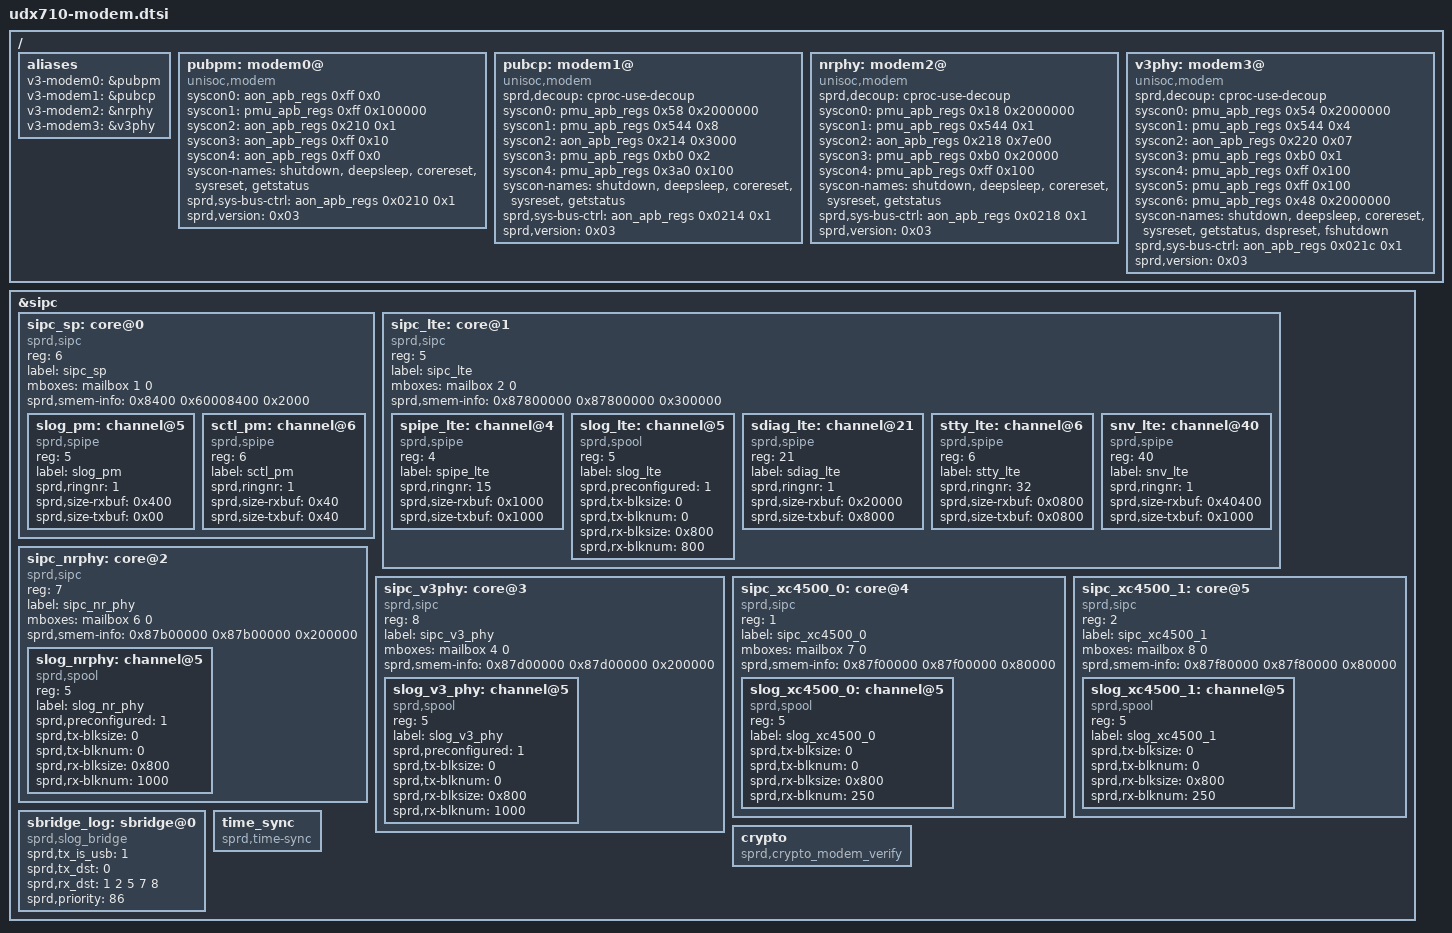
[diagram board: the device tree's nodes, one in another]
// SPDX-License-Identifier: GPL-2.0-only
/*
 * Unisoc UDX710 MODEM board DTSI file
 * This dt is used for modem drivers
 *
 * Copyright (C) 2018, Unisoc (Shanghai) Technologies Co., Ltd
 *
 * This file is licensed under a dual GPLv2 or X11 license.
 */
/ {
	aliases {
		v3-modem0 = &pubpm;
		v3-modem1 = &pubcp;
		v3-modem2 = &nrphy;
		v3-modem3 = &v3phy;
	};

	pubpm: modem0@ {
		compatible = "unisoc,modem";
		syscon0 = <&aon_apb_regs 0xff 0x0>;
		syscon1 = <&pmu_apb_regs 0xff 0x100000>;
		syscon2 = <&aon_apb_regs 0x210 0x1>;
		syscon3 = <&aon_apb_regs 0xff 0x10>;
		syscon4 = <&aon_apb_regs 0xff 0x0>;
		syscon-names = "shutdown", "deepsleep", "corereset",
				       "sysreset", "getstatus";
		sprd,sys-bus-ctrl = <&aon_apb_regs 0x0210 0x1>;
		sprd,version = <0x03>;
	};

	pubcp: modem1@ {
		compatible = "unisoc,modem";
		sprd,decoup = "cproc-use-decoup";
		syscon0 = <&pmu_apb_regs 0x58 0x2000000>;
		syscon1 = <&pmu_apb_regs 0x544 0x8>;
		syscon2 = <&aon_apb_regs 0x214 0x3000>;
		syscon3 = <&pmu_apb_regs 0xb0 0x2>;
		syscon4 = <&pmu_apb_regs 0x3a0 0x100>;
		syscon-names = "shutdown", "deepsleep", "corereset",
				       "sysreset", "getstatus";
		sprd,sys-bus-ctrl = <&aon_apb_regs 0x0214 0x1>;
		sprd,version = <0x03>;
	};

	nrphy: modem2@ {
		compatible = "unisoc,modem";
		sprd,decoup = "cproc-use-decoup";
		syscon0 = <&pmu_apb_regs 0x18 0x2000000>;
		syscon1 = <&pmu_apb_regs 0x544 0x1>;
		syscon2 = <&aon_apb_regs 0x218 0x7e00>;
		syscon3 = <&pmu_apb_regs 0xb0 0x20000>;
		syscon4 = <&pmu_apb_regs 0xff 0x100>;
		syscon-names = "shutdown", "deepsleep", "corereset",
				       "sysreset", "getstatus";
		sprd,sys-bus-ctrl = <&aon_apb_regs 0x0218 0x1>;
		sprd,version = <0x03>;
	};

	v3phy: modem3@ {
		compatible = "unisoc,modem";
		sprd,decoup = "cproc-use-decoup";
		syscon0 = <&pmu_apb_regs 0x54 0x2000000>;
		syscon1 = <&pmu_apb_regs 0x544 0x4>;
		syscon2 = <&aon_apb_regs 0x220 0x07>;
		syscon3 = <&pmu_apb_regs 0xb0 0x1>;
		syscon4 = <&pmu_apb_regs 0xff 0x100>;
		syscon5 = <&pmu_apb_regs 0xff 0x100>;
		syscon6 = <&pmu_apb_regs 0x48 0x2000000>;
		syscon-names = "shutdown", "deepsleep", "corereset",
				       "sysreset", "getstatus", "dspreset",
				       "fshutdown";
		sprd,sys-bus-ctrl = <&aon_apb_regs 0x021c 0x1>;
		sprd,version = <0x03>;
	};
};

&sipc {
	/* PM subsystem: 8KB */
	sipc_sp: core@0 {
		compatible = "sprd,sipc";
		#address-cells = <1>;
		#size-cells = <0>;
		/* endpoint id - should be same with sipc processor id */
		reg = <6>;
		label = "sipc_sp";
		/* <&mailbox  channel_id  is_no_wakeup(default 0)> */
		mboxes = <&mailbox 1 0>;
		/* This is temporary plan*/
		sprd,smem-info = <0x8400 0x60008400 0x2000>;

		slog_pm: channel@5 {
			compatible = "sprd,spipe";
			reg = <5>;
			label = "slog_pm";
			sprd,ringnr = <1>;
			sprd,size-rxbuf = <0x400>;	/* 1KB */
			sprd,size-txbuf = <0x00>;	/* 0k */
		};

		sctl_pm: channel@6 {
			compatible = "sprd,spipe";
			reg = <6>;
			label = "sctl_pm";
			sprd,ringnr = <1>;
			sprd,size-rxbuf = <0x40>;
			sprd,size-txbuf = <0x40>;
		};
	};

	/* PSCP: 3MB */
	sipc_lte: core@1 {
		compatible = "sprd,sipc";
		#address-cells = <1>;
		#size-cells = <0>;
		/* endpoint id - should be same with sipc processor id */
		reg = <5>;
		label = "sipc_lte";
		/* <&mailbox  channel_id  is_no_wakeup(default 0)> */
		mboxes = <&mailbox 2 0>;
		/* This is temporary plan*/
		sprd,smem-info = <0x87800000 0x87800000 0x300000>;

		spipe_lte: channel@4 {
			compatible = "sprd,spipe";
			/* channel number */
			reg = <4>;
			label = "spipe_lte";
			sprd,ringnr = <15>;
			sprd,size-rxbuf = <0x1000>;		/* 4*1024 */
			sprd,size-txbuf = <0x1000>;		/* 4*1024 */
		};

		slog_lte: channel@5 {
			compatible = "sprd,spool";
			/* channel number */
			reg = <5>;
			label = "slog_lte";
			sprd,preconfigured = <1>;
			sprd,tx-blksize = <0>;
			sprd,tx-blknum = <0>;
			sprd,rx-blksize = <0x800>; /* 2*1024 */
			sprd,rx-blknum = <800>;
		};

		sdiag_lte: channel@21 {
			compatible = "sprd,spipe";
			/* channel number */
			reg = <21>;
			label = "sdiag_lte";
			sprd,ringnr = <1>;
			sprd,size-rxbuf = <0x20000>;	/* 128*1024 */
			sprd,size-txbuf = <0x8000>;		/* 32*1024 */
		};

		stty_lte: channel@6 {
			compatible = "sprd,spipe";
			/* channel number */
			reg = <6>;
			label = "stty_lte";
			sprd,ringnr = <32>;
			sprd,size-rxbuf = <0x0800>;		/* 2*1024 */
			sprd,size-txbuf = <0x0800>;		/* 2*1024 */
		};

		snv_lte: channel@40 {
			compatible = "sprd,spipe";
			/* channel number */
			reg = <40>;
			label = "snv_lte";
			sprd,ringnr = <1>;
			sprd,size-rxbuf = <0x40400>;	/* 257*1024*/
			sprd,size-txbuf = <0x1000>;		/* 4*1024 */
		};
	};

	/* New Radio PHY: 2.0MB */
	sipc_nrphy: core@2 {
		compatible = "sprd,sipc";
		#address-cells = <1>;
		#size-cells = <0>;
		/* endpoint id - should be same with sipc processor id */
		reg = <7>;
		label = "sipc_nr_phy";
		/* <&mailbox  channel_id  is_no_wakeup(default 0)> */
		mboxes = <&mailbox 6 0>;
		/* This is temporary plan*/
		sprd,smem-info = <0x87b00000 0x87b00000 0x200000>;

		slog_nrphy: channel@5 {
			compatible = "sprd,spool";
			/* channel number */
			reg = <5>;
			label = "slog_nr_phy";
			sprd,preconfigured = <1>;
			sprd,tx-blksize = <0>;
			sprd,tx-blknum = <0>;
			sprd,rx-blksize = <0x800>; /* 2*1024 */
			sprd,rx-blknum = <1000>;
		};
	};

	/* MODEM v3 PHY: 2.0MB */
	sipc_v3phy: core@3 {
		compatible = "sprd,sipc";
		#address-cells = <1>;
		#size-cells = <0>;
		/* endpoint id - should be same with sipc processor id */
		reg = <8>;
		label = "sipc_v3_phy";
		/* <&mailbox  channel_id  is_no_wakeup(default 0)> */
		mboxes = <&mailbox 4 0>;
		/* This is temporary plan*/
		sprd,smem-info = <0x87d00000 0x87d00000 0x200000>;

		slog_v3_phy: channel@5 {
			compatible = "sprd,spool";
			/* channel number */
			reg = <5>;
			label = "slog_v3_phy";
			sprd,preconfigured = <1>;
			sprd,tx-blksize = <0>;
			sprd,tx-blknum = <0>;
			sprd,rx-blksize = <0x800>; /* 2*1024 */
			sprd,rx-blknum = <1000>;
		};
	};

	/* XC4500_0: 0.5MB */
	sipc_xc4500_0: core@4 {
		compatible = "sprd,sipc";
		#address-cells = <1>;
		#size-cells = <0>;
		/* endpoint id - should be same with sipc processor id */
		reg = <1>;
		label = "sipc_xc4500_0";
		/* <&mailbox  channel_id  is_no_wakeup(default 0)> */
		mboxes = <&mailbox 7 0>;
		/* This is temporary plan*/
		sprd,smem-info = <0x87f00000 0x87f00000 0x80000>;

		slog_xc4500_0: channel@5 {
			compatible = "sprd,spool";
			/* channel number */
			reg = <5>;
			label = "slog_xc4500_0";
			sprd,tx-blksize = <0>;
			sprd,tx-blknum = <0>;
			sprd,rx-blksize = <0x800>; /* 2*1024 */
			sprd,rx-blknum = <250>;
		};
	};

	/* XC4500_1: 0.5MB */
	sipc_xc4500_1: core@5 {
		compatible = "sprd,sipc";
		#address-cells = <1>;
		#size-cells = <0>;
		/* endpoint id - should be same with sipc processor id */
		reg = <2>;
		label = "sipc_xc4500_1";
		/* <&mailbox  channel_id  is_no_wakeup(default 0)> */
		mboxes = <&mailbox 8 0>;
		/* This is temporary plan*/
		sprd,smem-info = <0x87f80000 0x87f80000 0x80000>;

		slog_xc4500_1: channel@5 {
			compatible = "sprd,spool";
			/* channel number */
			reg = <5>;
			label = "slog_xc4500_1";
			sprd,tx-blksize = <0>;
			sprd,tx-blknum = <0>;
			sprd,rx-blksize = <0x800>; /* 2*1024 */
			sprd,rx-blknum = <250>;
		};
	};

/* Roc1: 48MB
 *	sipc_nr: core@6 {
 *		compatible = "sprd,sipc";
 *		#address-cells = <1>;
 *		#size-cells = <0>;
 *		sprd,type = "pcie";
 *		sprd,dst = <0>;
 *		sprd,client = <1>;
 *		sprd,ep-fun = <0>;
 *		sprd,smem-type = <1>;
 *		reg = <2>;
 *		label = "sipc-nr";
 *		mboxes = <&mailbox 8 0>;
 *		interrupts = <GIC_SPI 4 IRQ_TYPE_LEVEL_HIGH>;
 *		sprd,smem-info = <0x89600000 0x89600000 0x3000000>;
 *		sprd,high-offset = <0x00000000  0x00000000>;
 *
 *		spipe_nr: spipe@5 {
 *			compatible = "sprd,spipe";
 *			sprd,name = "spipe_nr";
 *			sprd,dst = <0>;
 *			sprd,channel = <4>;
 *			sprd,ringnr = <15>;
 *			sprd,size-rxbuf = <0x1000>;
 *			sprd,size-txbuf = <0x1000>;
 *		};
 *		sdiag_nr: spipe@6 {
 *			compatible = "sprd,spipe";
 *			sprd,name = "sdiag_nr";
 *			sprd,dst = <0>;
 *			sprd,channel = <21>;
 *			sprd,ringnr = <1>;
 *			sprd,size-rxbuf = <0x40000>;
 *			sprd,size-txbuf = <0x8000>;
 *		};
 *
 *		stty_nr: spipe@7 {
 *			compatible = "sprd,spipe";
 *			sprd,name = "stty_nr";
 *			sprd,dst = <0>;
 *			sprd,channel = <6>;
 *			sprd,ringnr = <32>;
 *			sprd,size-rxbuf = <0x0800>;
 *			sprd,size-txbuf = <0x0800>;
 *		};
 *		snv_nr: spipe@9 {
 *			compatible = "sprd,spipe";
 *			sprd,name = "snv_nr";
 *			sprd,dst = <0>;
 *			sprd,channel = <40>;
 *			sprd,ringnr = <1>;
 *			sprd,size-rxbuf = <0x40400>;
 *			sprd,size-txbuf = <0x1000>;
 *		};
 *
 *		slog_nr: spool@5{
 *			compatible = "sprd,spool";
 *			sprd,name = "slog_nr";
 *			sprd,dst = <0>;
 *			sprd,channel = <5>;
 *			sprd,tx-blksize = <0>;
 *			sprd,tx-blknum = <0>;
 *			sprd,rx-blksize = <0x10000>;
 *			sprd,rx-blknum = <128>;
 *		};
 *	};
 */
	sbridge_log: sbridge@0 {
		compatible = "sprd,slog_bridge";
		sprd,tx_is_usb = <1>;
		sprd,tx_dst = <0>;
		sprd,rx_dst = <1 2 5 7 8>;
		sprd,priority = <86>;
	};

	crypto {
		compatible = "sprd,crypto_modem_verify";
	};

	time_sync {
		compatible = "sprd,time-sync";
	};
};
